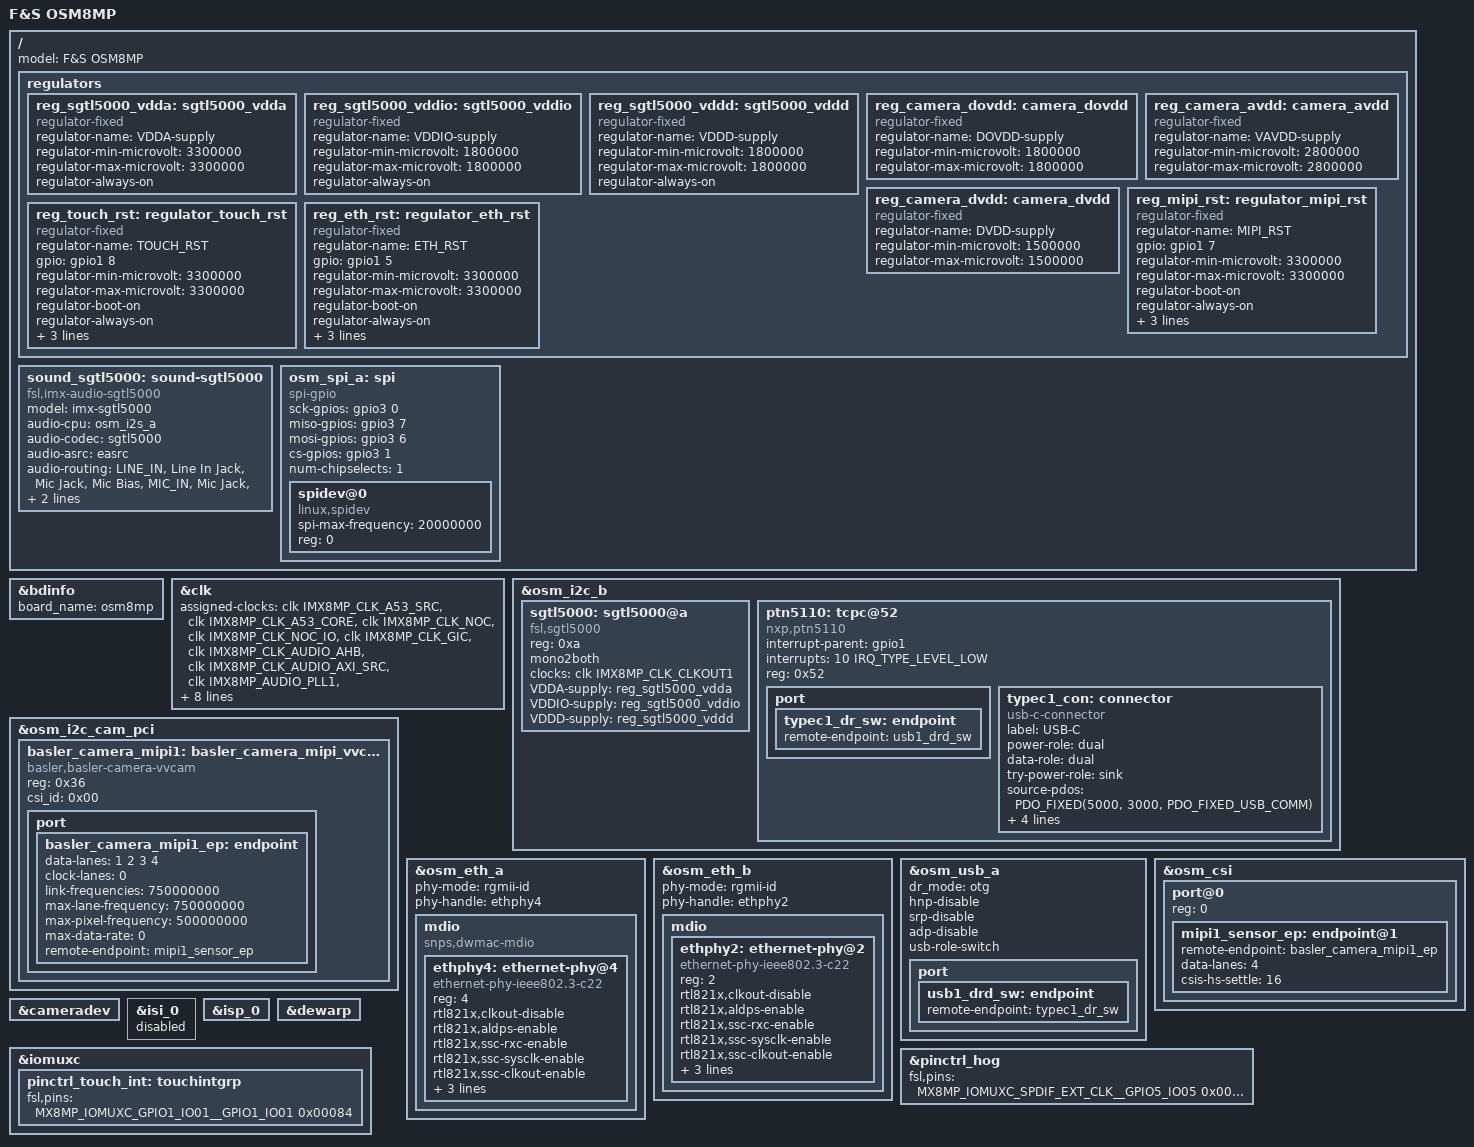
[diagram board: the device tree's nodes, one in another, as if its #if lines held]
/*
 * Copyright (C) 2024 F&S Elektronik Systeme GmbH
 *
 * This program is free software; you can redistribute it and/or modify
 * it under the terms of the GNU General Public License version 2 as
 * published by the Free Software Foundation.
 */

/dts-v1/;

/* Set board revision as 3-digit number, e.g. 110 for board rev. 1.10 */
#define CONFIG_OSM8MP_BOARD_REVISION	100
/* Set adapter revision as 3-digit number, e.g. 110 for board rev. 1.10 */
#define CONFIG_ADP_OSM_BOARD_REVISION	120
/* Set baseboard revision as 3-digit number, e.g. 110 for board rev. 1.10 */
#define CONFIG_PICOCOREBBDSI_BOARD_REVISION	140

/* Activate this if you want to use the Cortex-M4 core */
//#define SUPPORT_M4

/* Display device-trees enables MIPI DSI */
/* MIPI DSI */
//#define CONFIG_OSM8MP_MIPI_DSI

/* CAN */
#define CONFIG_OSM8MP_CAN_A
//#define CONFIG_OSM8MP_CAN_B

/* Network */
#define CONFIG_OSM8MP_ETH_A
#define CONFIG_OSM8MP_ETH_B

/* USB */
#define CONFIG_OSM8MP_USB_A
#define CONFIG_OSM8MP_USB_A_USBC
#define CONFIG_OSM8MP_USB_A_USBC_ALERT
//#define CONFIG_OSM8MP_USB_C

/* PCIe */
#define CONFIG_OSM8MP_PCIE_A

/* I2C */
#define CONFIG_OSM8MP_I2C_A /* OSM: EEPROM BB: I2C_A */
#define CONFIG_OSM8MP_I2C_B /* ADP: SGTL5000 BB: I2C_D */
/* OSM: I2C_CAM_PCI ADP: I2C_CAM  BB: I2C_B */
/* OSM: I2C_CAM_PCI ADP: MPCIE_SM BB: I2C_C */
#define CONFIG_OSM8MP_I2C_CAM_PCI

/* PWM and backlight brightness */
//#define CONFIG_OSM8MP_BL_CTRL
#define CONFIG_OSM8MP_PWM_0
#define CONFIG_OSM8MP_PWM_1

/* UART_CON - ttymxc0 */
#define CONFIG_OSM8MP_UART_CON

/* UART_A - ttymxc1 - Not connected */
//#define CONFIG_OSM8MP_UART_A
//#define CONFIG_OSM8MP_UART_A_RTSCTS

/* UART_B - ttymxc2 */
#define CONFIG_OSM8MP_UART_B
#define CONFIG_OSM8MP_UART_B_RTSCTS

/* UART_C - ttymxc3 */
#define CONFIG_OSM8MP_UART_C

/* FSPI (Single/Dual/Quad) -> Uncommented because of SPI-GPIO */
//#define CONFIG_OSM8MP_SPI_A
#define CONFIG_OSM8MP_SPI_B

/* Audio */
#define CONFIG_OSM8MP_I2S_A
//#define CONFIG_OSM8MP_I2S_B

/* Camera on serial MIPI CSI interface */
#define CONFIG_OSM8MP_SERIAL_CAMERA
/* Experimental implementation for Basler dart daA3840-30mci.
 * Define CONFIG_OSM8MP_SERIAL_CAMERA must also be set.
 */

/* SDIO */
#define CONFIG_OSM8MP_SDIO_A
#define CONFIG_OSM8MP_SDIO_A_CD
#define CONFIG_OSM8MP_SDIO_A_WP

//#define CONFIG_OSM8MP_SDIO_B
//#define CONFIG_OSM8MP_SDIO_B_CD
//#define CONFIG_OSM8MP_SDIO_B_WP
//#define CONFIG_OSM8MP_SDIO_B_8_Bit

/* Check for invalid CONFIG combinations */

/*
 * Exclude devices from Linux that are used by the Cortex-M4 FreeRTOS examples
 *
 * - UART_D: Debug Console for Cortex-M4
 * - I2C_A:  I2C Bus used in I2C examples
 * - I2C_D:  I2C Bus used by the Audio Codec in SAI examples
 * - SPI_B:  SPI_B is used for ECSPI examples
 * - SDMA1:  Gets removed at another Point, it is used by SPI_B and UART driver
 *           examples
 * - SPI_A:  SPI_A using SDMA1 but SDMA1 is excluded so also exclude SPI_A
 *
 * In addition the following pins are already predefined in FreeRTOS to be used
 * as arbitrary GPIOs. Please remove the comment of the appropriate line of
 * each device from which you use any signal in your own application.
 *
 * - AUDIO_3: GPT capture driver example uses one of its Pins
 */
#ifdef SUPPORT_M4
#undef CONFIG_OSM8MP_UART_C
//#undef CONFIG_OSM8MP_I2C_A
//#undef CONFIG_OSM8MP_SPI_A
//#undef CONFIG_OSM8MP_SPI_B
/* Only undef if using audio/sai examples */
//#undef CONFIG_OSM8MP_I2C_B
//#undef CONFIG_OSM8MP_I2S_A
#endif

/* Disable PWM_0 if BL_CTRL is enabled */
#ifdef CONFIG_OSM8MP_BL_CTRL
#undef CONFIG_OSM8MP_PWM_0
#endif

/* Disable PWM_2 if SPI_A_CS1 is enabled */
#ifdef CONFIG_OSM8MP_SPI_A_CS1
#undef CONFIG_OSM8MP_PWM_2
#endif

/* Disable PWM_2 if SPI_B_CS1 is enabled */
#ifdef CONFIG_OSM8MP_SPI_B_CS1
#undef CONFIG_OSM8MP_PWM_3
#endif

/* Set different settings for corresponding baseboard revision */
#if CONFIG_PICOCOREBBDSI_BOARD_REVISION < 130
#undef CONFIG_OSM8MP_USB_A_USBC
#endif

#if !defined(CONFIG_OSM8MP_USB_A_USBC) \
    || (CONFIG_PICOCOREBBDSI_BOARD_REVISION < 140)
#undef CONFIG_OSM8MP_USB_A_USBC_ALERT
#endif

#include "osm8mp.dtsi"

/* osm_spi_a overwritten by SPI bitbanging driver */
/delete-node/ &osm_spi_a;

/ {
	model = "F&S OSM8MP";

	regulators {
		/* SGTL5000 analog voltage */
		reg_sgtl5000_vdda: sgtl5000_vdda {
			compatible = "regulator-fixed";
			regulator-name = "VDDA-supply";
			regulator-min-microvolt = <3300000>;
			regulator-max-microvolt = <3300000>;
			regulator-always-on;
		};

		/* SGTL5000 I/O voltage */
		reg_sgtl5000_vddio: sgtl5000_vddio {
			compatible = "regulator-fixed";
			regulator-name = "VDDIO-supply";
			regulator-min-microvolt = <1800000>;
			regulator-max-microvolt = <1800000>;
			regulator-always-on;
		};

		/* SGTL5000 internal digital voltage */
		reg_sgtl5000_vddd: sgtl5000_vddd {
			compatible = "regulator-fixed";
			regulator-name = "VDDD-supply";
			regulator-min-microvolt = <1800000>;
			regulator-max-microvolt = <1800000>;
			regulator-always-on;
		};

#ifdef CONFIG_OSM8MP_CAMERA
		reg_camera_dovdd: camera_dovdd {
			compatible = "regulator-fixed";
			regulator-name = "DOVDD-supply";
			regulator-min-microvolt = <1800000>;
			regulator-max-microvolt = <1800000>;
		};

		reg_camera_avdd: camera_avdd {
			compatible = "regulator-fixed";
			regulator-name = "VAVDD-supply";
			regulator-min-microvolt = <2800000>;
			regulator-max-microvolt = <2800000>;
		};

		reg_camera_dvdd: camera_dvdd {
			compatible = "regulator-fixed";
			regulator-name = "DVDD-supply";
			regulator-min-microvolt = <1500000>;
			regulator-max-microvolt = <1500000>;
		};
#endif /* CONFIG_OSM8MP_CAMERA */

		reg_mipi_rst: regulator_mipi_rst {
			compatible = "regulator-fixed";
			regulator-name = "MIPI_RST";
			gpio = <&gpio1 7 GPIO_ACTIVE_HIGH>;
			regulator-min-microvolt = <3300000>;
			regulator-max-microvolt = <3300000>;
			regulator-boot-on;
			regulator-always-on;
			enable-active-high;
			startup-delay-us = <1000>;
			off-on-delay-us = <12000>;
		};

		reg_touch_rst: regulator_touch_rst {
			compatible = "regulator-fixed";
			regulator-name = "TOUCH_RST";
			gpio = <&gpio1 8 GPIO_ACTIVE_HIGH>;
			regulator-min-microvolt = <3300000>;
			regulator-max-microvolt = <3300000>;
			regulator-boot-on;
			regulator-always-on;
			enable-active-high;
			startup-delay-us = <1000>;
			off-on-delay-us = <12000>;
		};

#if CONFIG_ADP_OSM_BOARD_REVISION >= 120
		reg_eth_rst: regulator_eth_rst {
			compatible = "regulator-fixed";
			regulator-name = "ETH_RST";
			gpio = <&gpio1 5 GPIO_ACTIVE_HIGH>;
			regulator-min-microvolt = <3300000>;
			regulator-max-microvolt = <3300000>;
			regulator-boot-on;
			regulator-always-on;
			enable-active-high;
			startup-delay-us = <1000>;
			off-on-delay-us = <12000>;
		};
#endif
	};

	sound_sgtl5000: sound-sgtl5000 {
		compatible = "fsl,imx-audio-sgtl5000";
		model = "imx-sgtl5000";
		audio-cpu = <&osm_i2s_a>;
		audio-codec = <&sgtl5000>;
		audio-asrc = <&easrc>;
		audio-routing =
			"LINE_IN", "Line In Jack",
			"Mic Jack", "Mic Bias",
			"MIC_IN", "Mic Jack",
			"Line Out Jack", "LINE_OUT",
			"Headphone Jack", "HP_OUT";
	};

	/* SPI bitbanging driver */
	osm_spi_a: spi {
		compatible = "spi-gpio";
		#address-cells = <0x1>;
		#size-cells = <0x0>;

		sck-gpios = <&gpio3 0 0>;
		miso-gpios = <&gpio3 7 0>;
		mosi-gpios = <&gpio3 6 0>;
		cs-gpios = <&gpio3 1 0>;
		num-chipselects = <1>;

		spidev@0 {
			compatible = "linux,spidev";
			spi-max-frequency = <20000000>;
			reg = <0>;
			status = "okay";
		};
	};
};

&bdinfo{
	board_name = "osm8mp";
};

#if CONFIG_ADP_OSM_BOARD_REVISION < 120
#if defined(CONFIG_OSM8MP_MIPI_DSI) \
|| defined(CONFIG_OSM8MP_MIPI_DSI_LVDS)
&reg_vlcd {
	gpio = <&gpio1 5 GPIO_ACTIVE_HIGH>;
};
#endif

#ifdef CONFIG_OSM8MP_BL_CTRL
&reg_ldb_bl {
	gpio = <&gpio1 6 GPIO_ACTIVE_HIGH>;
};
#endif
#endif

&clk {
	assigned-clocks = <&clk IMX8MP_CLK_A53_SRC>,
			  <&clk IMX8MP_CLK_A53_CORE>,
			  <&clk IMX8MP_CLK_NOC>,
			  <&clk IMX8MP_CLK_NOC_IO>,
			  <&clk IMX8MP_CLK_GIC>,
			  <&clk IMX8MP_CLK_AUDIO_AHB>,
			  <&clk IMX8MP_CLK_AUDIO_AXI_SRC>,
			  <&clk IMX8MP_AUDIO_PLL1>,
			  <&clk IMX8MP_AUDIO_PLL2>,
			  <&clk IMX8MP_VIDEO_PLL1>,
			  <&clk IMX8MP_CLK_CLKOUT1>;
	assigned-clock-rates = <0>, <0>,
			       <1000000000>,
			       <800000000>,
			       <500000000>,
			       <400000000>,
			       <800000000>,
			       <393216000>,
			       <361267200>,
			       <1039500000>,
			       <24576000>;

	init-on-array = <IMX8MP_CLK_HSIO_ROOT>, <IMX8MP_CLK_CLKOUT1>;
};

&osm_i2c_b {
	sgtl5000: sgtl5000@a {
		compatible = "fsl,sgtl5000";
		reg = <0xa>;
		mono2both;
		clocks = <&clk IMX8MP_CLK_CLKOUT1>;
		VDDA-supply = <&reg_sgtl5000_vdda>;
		VDDIO-supply = <&reg_sgtl5000_vddio>;
		VDDD-supply = <&reg_sgtl5000_vddd>;
	};

#ifdef CONFIG_OSM8MP_USB_A_USBC
	/* USB-C */
	ptn5110: tcpc@52 {
		compatible = "nxp,ptn5110";
#ifdef CONFIG_OSM8MP_USB_A_USBC_ALERT
		interrupt-parent = <&gpio1>;
		interrupts = <10 IRQ_TYPE_LEVEL_LOW>;
#endif
		reg = <0x52>;
		status = "okay";

		port {
			typec1_dr_sw: endpoint {
				remote-endpoint = <&usb1_drd_sw>;
			};
		};

		typec1_con: connector {
			compatible = "usb-c-connector";
			label = "USB-C";
			power-role = "dual";
			data-role = "dual";
			try-power-role = "sink";
			source-pdos = <PDO_FIXED(5000, 3000,
			PDO_FIXED_USB_COMM)>;
			sink-pdos = <PDO_FIXED(5000, 3000, PDO_FIXED_USB_COMM)
				     PDO_VAR(5000, 20000, 3000)>;
			op-sink-microwatt = <15000000>;
			self-powered;
		};
	};
#endif
};

&osm_i2c_cam_pci {
	basler_camera_mipi1: basler_camera_mipi_vvcam@36 {
		compatible = "basler,basler-camera-vvcam", "basler-camera-vvcam";
		reg = <0x36>;
		csi_id = <0x00>;
		status = "okay";

		port {
			basler_camera_mipi1_ep: endpoint {
				data-lanes = <1 2 3 4>;
				clock-lanes = <0>;
				link-frequencies = /bits/ 64 <750000000>;
				max-lane-frequency = /bits/ 64 <750000000>;
				max-pixel-frequency = /bits/ 64 <500000000>;
				max-data-rate = /bits/ 64 <0>;
				remote-endpoint = <&mipi1_sensor_ep>;
			};
		};
	};
};

#if 0
/* SPI not implemented in NXP FlexSPI driver, so use SPI-GPIO */
&osm_spi_a {
	cs-gpios = <0>;

	spidev@0 {
		spi-tx-bus-width = <1>;
		spi-rx-bus-width = <1>;
	};
};
#endif

&osm_eth_a {
	phy-mode = "rgmii-id";
	phy-handle = <&ethphy4>;

	mdio {
		compatible = "snps,dwmac-mdio";
		#address-cells = <1>;
		#size-cells = <0>;

		ethphy4: ethernet-phy@4 {
			compatible = "ethernet-phy-ieee802.3-c22";
			reg = <4>;
			rtl821x,clkout-disable;
			rtl821x,aldps-enable;
			rtl821x,ssc-rxc-enable;
			rtl821x,ssc-sysclk-enable;
			rtl821x,ssc-clkout-enable;
			rtl821x,led-link = <2>; // LED1 for link indication
			rtl821x,led-act = <2>; // LED1 for activity
			eee-broken-1000t;
		};
	};
};

&osm_eth_b {
	phy-mode = "rgmii-id";
	phy-handle = <&ethphy2>;

	mdio {
		#address-cells = <1>;
		#size-cells = <0>;

		ethphy2: ethernet-phy@2 {
			compatible = "ethernet-phy-ieee802.3-c22";
			reg = <2>;
			rtl821x,clkout-disable;
			rtl821x,aldps-enable;
			rtl821x,ssc-rxc-enable;
			rtl821x,ssc-sysclk-enable;
			rtl821x,ssc-clkout-enable;
			rtl821x,led-link = <2>; // LED1 for link indication
			rtl821x,led-act = <2>; // LED1 for activity
			eee-broken-1000t;
		};
	};
};

&osm_usb_a {
	dr_mode = "otg";
#ifdef CONFIG_OSM8MP_USB_A_USBC
	hnp-disable;
	srp-disable;
	adp-disable;
	usb-role-switch;

	port {
		usb1_drd_sw: endpoint {
			remote-endpoint = <&typec1_dr_sw>;
		};
	};
#endif
};

&osm_csi {
	/delete-property/ csi,mipi_rst;

	port@0 {
		reg = <0>;
		mipi1_sensor_ep: endpoint@1 {
			remote-endpoint = <&basler_camera_mipi1_ep>;
			data-lanes = <4>;
			csis-hs-settle = <16>;
		};
	};
};

&cameradev {
	status = "okay";
};

&isi_0 {
	status = "disabled";
};

&isp_0 {
	status = "okay";
};

&dewarp {
	status = "okay";
};

&iomuxc {
#ifdef IMX8MP_TOUCH_INTERRUPT_PINCTRL
	pinctrl_touch_int: touchintgrp {
		fsl,pins = <
			MX8MP_IOMUXC_GPIO1_IO01__GPIO1_IO01	0x00084
		>;
	};
#endif
};

&pinctrl_hog {
	fsl,pins = <
		/* CARRIER_PWR_EN */
		MX8MP_IOMUXC_SPDIF_EXT_CLK__GPIO5_IO05	0x00004

		/* GPIO_A */
		/* 0 */ MX8MP_IOMUXC_GPIO1_IO05__GPIO1_IO05	0x00004
		/* 1 */ MX8MP_IOMUXC_GPIO1_IO06__GPIO1_IO06	0x00004
		/* 2 */ MX8MP_IOMUXC_GPIO1_IO07__GPIO1_IO07	0x00004
#ifndef IMX8MP_TOUCH_INTERRUPT_PINCTRL
		/* 3 */ MX8MP_IOMUXC_GPIO1_IO01__GPIO1_IO01	0x00004
#endif
		/* 4 */ MX8MP_IOMUXC_GPIO1_IO10__GPIO1_IO10	0x00004
		/* 5 */ MX8MP_IOMUXC_GPIO1_IO08__GPIO1_IO08	0x00004
#ifndef CONFIG_OSM8MP_PWM_2
#ifndef CONFIG_OSM8MP_SPI_A_CS1
		/* 6 */ MX8MP_IOMUXC_SAI5_RXD0__GPIO3_IO21	0x00004
#endif
#endif
#ifndef CONFIG_OSM8MP_PWM_3
#ifndef CONFIG_OSM8MP_SPI_B_CS1
		/* 7 */ MX8MP_IOMUXC_SAI5_RXC__GPIO3_IO20	0x00004
#endif
#endif
		/* GPIO_B */
		/* 0 */ MX8MP_IOMUXC_GPIO1_IO03__GPIO1_IO03	0x00004
		/* 1 */ MX8MP_IOMUXC_GPIO1_IO11__GPIO1_IO11	0x00004
		/* 2 */ MX8MP_IOMUXC_GPIO1_IO00__GPIO1_IO00	0x00004
		/* 3 */ MX8MP_IOMUXC_GPIO1_IO09__GPIO1_IO09	0x00004
		/* 4 */ MX8MP_IOMUXC_SAI5_RXD3__GPIO3_IO24	0x00004
		/* 5 */ MX8MP_IOMUXC_SAI2_RXC__GPIO4_IO22	0x00004
		/* 6 */ MX8MP_IOMUXC_SAI5_RXD2__GPIO3_IO23	0x00004
		/* 7 */ MX8MP_IOMUXC_SAI2_RXFS__GPIO4_IO21	0x00004

		/* GPIO_C */
		/* 0 */ MX8MP_IOMUXC_SAI2_MCLK__GPIO4_IO27	0x00004
		/* 1 */ MX8MP_IOMUXC_SAI1_RXD1__GPIO4_IO03	0x00004
		/* 2 */ MX8MP_IOMUXC_SAI1_TXD7__GPIO4_IO19	0x00004
		/* 3 */ MX8MP_IOMUXC_SAI1_TXD6__GPIO4_IO18	0x00004
		/* 4 */ /* VDD_EN: Disable display for usage */
		/* 4 */ MX8MP_IOMUXC_SAI1_RXFS__GPIO4_IO00	0x00004
		/* 5 */ /* BL_EN: Disable backlight control for usage */
		/* 5 */ MX8MP_IOMUXC_SAI1_MCLK__GPIO4_IO20	0x00004
		/* 6 */ /* CAM_EN: Disable CAM for usage */
		/* 6 */ MX8MP_IOMUXC_SAI1_RXC__GPIO4_IO01	0x00004
		/* 7 */ /* CAM_RST: Disable CAM for usage */
		/* 7 */ MX8MP_IOMUXC_SAI1_RXD0__GPIO4_IO02	0x00004

#if !defined(CONFIG_OSM8MP_BL_CTRL) && !defined(CONFIG_OSM8MP_PWM_0)
		MX8MP_IOMUXC_SAI5_RXFS__GPIO3_IO19	0x00004
#endif

#ifndef CONFIG_OSM8MP_PWM_1
		MX8MP_IOMUXC_SAI5_MCLK__GPIO3_IO25	0x00004
#endif

#ifndef CONFIG_OSM8MP_SPI_A
		MX8MP_IOMUXC_NAND_ALE__GPIO3_IO00		0x00004
		MX8MP_IOMUXC_NAND_DATA00__GPIO3_IO06	0x00004
		MX8MP_IOMUXC_NAND_DATA01__GPIO3_IO07	0x00004
		MX8MP_IOMUXC_NAND_DATA02__GPIO3_IO08	0x00004
		MX8MP_IOMUXC_NAND_DATA03__GPIO3_IO09	0x00004
		MX8MP_IOMUXC_NAND_CE0_B__GPIO3_IO01		0x00004
#endif
#ifndef CONFIG_OSM8MP_SPI_A_HIGHSPEED
		/* Enable DSI_TE functionality */
		MX8MP_IOMUXC_NAND_DQS__GPIO3_IO14		0x00004
#endif

#ifndef CONFIG_OSM8MP_SPI_B
		MX8MP_IOMUXC_ECSPI2_SCLK__GPIO5_IO10	0x00004
		MX8MP_IOMUXC_ECSPI2_MOSI__GPIO5_IO11	0x00004
		MX8MP_IOMUXC_ECSPI2_MISO__GPIO5_IO12	0x00004
		MX8MP_IOMUXC_ECSPI1_SS0__GPIO5_IO09		0x00004
#endif

#ifndef CONFIG_OSM8MP_ETH_A
		MX8MP_IOMUXC_ENET_MDC__GPIO1_IO16		0x00004
		MX8MP_IOMUXC_ENET_MDIO__GPIO1_IO17		0x00004
		MX8MP_IOMUXC_ENET_RD0__GPIO1_IO26		0x00004
		MX8MP_IOMUXC_ENET_RD1__GPIO1_IO27		0x00004
		MX8MP_IOMUXC_ENET_RD2__GPIO1_IO28		0x00004
		MX8MP_IOMUXC_ENET_RD3__GPIO1_IO29		0x00004
		MX8MP_IOMUXC_ENET_RXC__GPIO1_IO25		0x00004
		MX8MP_IOMUXC_ENET_RX_CTL__GPIO1_IO24	0x00004
		MX8MP_IOMUXC_ENET_TD0__GPIO1_IO21		0x00004
		MX8MP_IOMUXC_ENET_TD1__GPIO1_IO20		0x00004
		MX8MP_IOMUXC_ENET_TD2__GPIO1_IO19		0x00004
		MX8MP_IOMUXC_ENET_TD3__GPIO1_IO18		0x00004
		MX8MP_IOMUXC_ENET_TX_CTL__GPIO1_IO22	0x00004
		MX8MP_IOMUXC_ENET_TXC__GPIO1_IO23		0x00004
#endif

#ifndef CONFIG_OSM8MP_ETH_B
		MX8MP_IOMUXC_SAI1_RXD2__GPIO4_IO04	0x00004
		MX8MP_IOMUXC_SAI1_RXD3__GPIO4_IO05	0x00004
		MX8MP_IOMUXC_SAI1_RXD4__GPIO4_IO06	0x00004
		MX8MP_IOMUXC_SAI1_RXD5__GPIO4_IO07	0x00004
		MX8MP_IOMUXC_SAI1_RXD6__GPIO4_IO08	0x00004
		MX8MP_IOMUXC_SAI1_RXD7__GPIO4_IO09	0x00004
		MX8MP_IOMUXC_SAI1_TXC__GPIO4_IO11	0x00004
		MX8MP_IOMUXC_SAI1_TXFS__GPIO4_IO10	0x00004
		MX8MP_IOMUXC_SAI1_TXD0__GPIO4_IO12	0x00004
		MX8MP_IOMUXC_SAI1_TXD1__GPIO4_IO13	0x00004
		MX8MP_IOMUXC_SAI1_TXD2__GPIO4_IO14	0x00004
		MX8MP_IOMUXC_SAI1_TXD3__GPIO4_IO15	0x00004
		MX8MP_IOMUXC_SAI1_TXD4__GPIO4_IO16	0x00004
		MX8MP_IOMUXC_SAI1_TXD5__GPIO4_IO17	0x00004
#endif

#ifndef CONFIG_OSM8MP_CAN_A
		MX8MP_IOMUXC_SPDIF_RX__GPIO5_IO04	0x00004
		MX8MP_IOMUXC_SPDIF_TX__GPIO5_IO03	0x00004
#endif

#ifndef CONFIG_OSM8MP_CAN_B
		MX8MP_IOMUXC_HDMI_HPD__GPIO3_IO29	0x00004
		MX8MP_IOMUXC_HDMI_CEC__GPIO3_IO28	0x00004
#endif

#ifndef CONFIG_OSM8MP_I2C_A
		MX8MP_IOMUXC_I2C3_SCL__GPIO5_IO18		0x00004
		MX8MP_IOMUXC_I2C3_SDA__GPIO5_IO19		0x00004
#endif

#ifndef CONFIG_OSM8MP_I2C_B
		MX8MP_IOMUXC_I2C4_SCL__GPIO5_IO20		0x00004
		MX8MP_IOMUXC_I2C4_SDA__GPIO5_IO21		0x00004
#endif

#ifndef CONFIG_OSM8MP_I2C_CAM_PCI
		MX8MP_IOMUXC_HDMI_DDC_SCL__GPIO3_IO26	0x00004
		MX8MP_IOMUXC_HDMI_DDC_SDA__GPIO3_IO27	0x00004
#endif

#ifndef CONFIG_OSM8MP_PCIE_A
		MX8MP_IOMUXC_SAI5_RXD1__GPIO3_IO22		0x00004
		MX8MP_IOMUXC_SAI3_RXC__GPIO4_IO29		0x00004
		MX8MP_IOMUXC_SAI3_RXFS__GPIO4_IO28		0x00004
		MX8MP_IOMUXC_NAND_CE1_B__GPIO3_IO02		0x00004
#endif

#ifndef CONFIG_OSM8MP_I2S_A
		MX8MP_IOMUXC_SAI2_TXFS__GPIO4_IO24	0x00004
		MX8MP_IOMUXC_SAI2_TXC__GPIO4_IO25	0x00004
		MX8MP_IOMUXC_SAI2_TXD0__GPIO4_IO26	0x00004
		MX8MP_IOMUXC_SAI2_RXD0__GPIO4_IO23	0x00004
#endif

#ifndef CONFIG_OSM8MP_I2S_B
		MX8MP_IOMUXC_SAI3_TXFS__GPIO4_IO31	0x00004
		MX8MP_IOMUXC_SAI3_TXC__GPIO5_IO00	0x00004
		MX8MP_IOMUXC_SAI3_TXD__GPIO5_IO01	0x00004
		MX8MP_IOMUXC_SAI3_RXD__GPIO4_IO30	0x00004
#endif

#ifndef CONFIG_OSM8MP_UART_A
		MX8MP_IOMUXC_UART1_RXD__GPIO5_IO22		0x00004
		MX8MP_IOMUXC_UART1_TXD__GPIO5_IO23		0x00004
#endif
#ifndef CONFIG_OSM8MP_UART_A_RTSCTS
		MX8MP_IOMUXC_UART3_RXD__GPIO5_IO26		0x00004
		MX8MP_IOMUXC_UART3_TXD__GPIO5_IO27		0x00004
#endif

#ifndef CONFIG_OSM8MP_UART_B
		MX8MP_IOMUXC_ECSPI1_SCLK__GPIO5_IO06 	0x00004
		MX8MP_IOMUXC_ECSPI1_MOSI__GPIO5_IO07	0x00004
#endif
#ifndef CONFIG_OSM8MP_UART_B_RTSCTS
		MX8MP_IOMUXC_ECSPI1_MISO__GPIO5_IO08	0x00004
		MX8MP_IOMUXC_ECSPI1_SS0__GPIO5_IO09		0x00004
#endif

#ifndef CONFIG_OSM8MP_UART_C
		MX8MP_IOMUXC_UART4_RXD__GPIO5_IO28		0x00004
		MX8MP_IOMUXC_UART4_TXD__GPIO5_IO29		0x00004
#endif

#ifndef CONFIG_OSM8MP_UART_CON
		MX8MP_IOMUXC_UART2_RXD__GPIO5_IO24		0x00004
		MX8MP_IOMUXC_UART2_TXD__GPIO5_IO25		0x00004
#endif

#ifndef CONFIG_OSM8MP_USB_A
		MX8MP_IOMUXC_GPIO1_IO12__GPIO1_IO12	0x00004
#endif

#ifndef CONFIG_OSM8MP_USB_C
		MX8MP_IOMUXC_GPIO1_IO14__GPIO1_IO14	0x00004
#endif

#ifndef CONFIG_OSM8MP_SDIO_A
		MX8MP_IOMUXC_SD2_RESET_B__GPIO2_IO19	0x00004
		MX8MP_IOMUXC_SD2_CLK__GPIO2_IO13		0x00004
		MX8MP_IOMUXC_SD2_CMD__GPIO2_IO14		0x00004
		MX8MP_IOMUXC_SD2_DATA0__GPIO2_IO15		0x00004
		MX8MP_IOMUXC_SD2_DATA1__GPIO2_IO16		0x00004
		MX8MP_IOMUXC_SD2_DATA2__GPIO2_IO17		0x00004
		MX8MP_IOMUXC_SD2_DATA3__GPIO2_IO18		0x00004
#endif
#ifndef CONFIG_OSM8MP_SDIO_A_CD
		MX8MP_IOMUXC_SD2_CD_B__GPIO2_IO12		0x00004
#endif
#ifndef CONFIG_OSM8MP_SDIO_A_WP
		MX8MP_IOMUXC_SD2_WP__GPIO2_IO20			0x00004
#endif

#ifndef CONFIG_OSM8MP_SDIO_B
			MX8MP_IOMUXC_NAND_READY_B__GPIO3_IO16	0x00004
			MX8MP_IOMUXC_NAND_WE_B__GPIO3_IO17		0x00004
			MX8MP_IOMUXC_NAND_WP_B__GPIO3_IO18		0x00004
			MX8MP_IOMUXC_NAND_DATA04__GPIO3_IO10	0x00004
			MX8MP_IOMUXC_NAND_DATA05__GPIO3_IO11	0x00004
			MX8MP_IOMUXC_NAND_DATA06__GPIO3_IO12	0x00004
			MX8MP_IOMUXC_NAND_DATA07__GPIO3_IO13	0x00004
#endif
#ifndef CONFIG_OSM8MP_SDIO_B_CD
			MX8MP_IOMUXC_I2C2_SCL__GPIO5_IO16		0x00004
#endif
#ifndef CONFIG_OSM8MP_SDIO_B_WP
			MX8MP_IOMUXC_I2C2_SDA__GPIO5_IO17		0x00004
#endif
#ifndef CONFIG_OSM8MP_SDIO_B_8_Bit
			MX8MP_IOMUXC_NAND_RE_B__GPIO3_IO15		0x00004
			MX8MP_IOMUXC_NAND_CE2_B__GPIO3_IO03		0x00004
			MX8MP_IOMUXC_NAND_CE3_B__GPIO3_IO04		0x00004
			MX8MP_IOMUXC_NAND_CLE__GPIO3_IO05		0x00004
#endif
	>;
};
